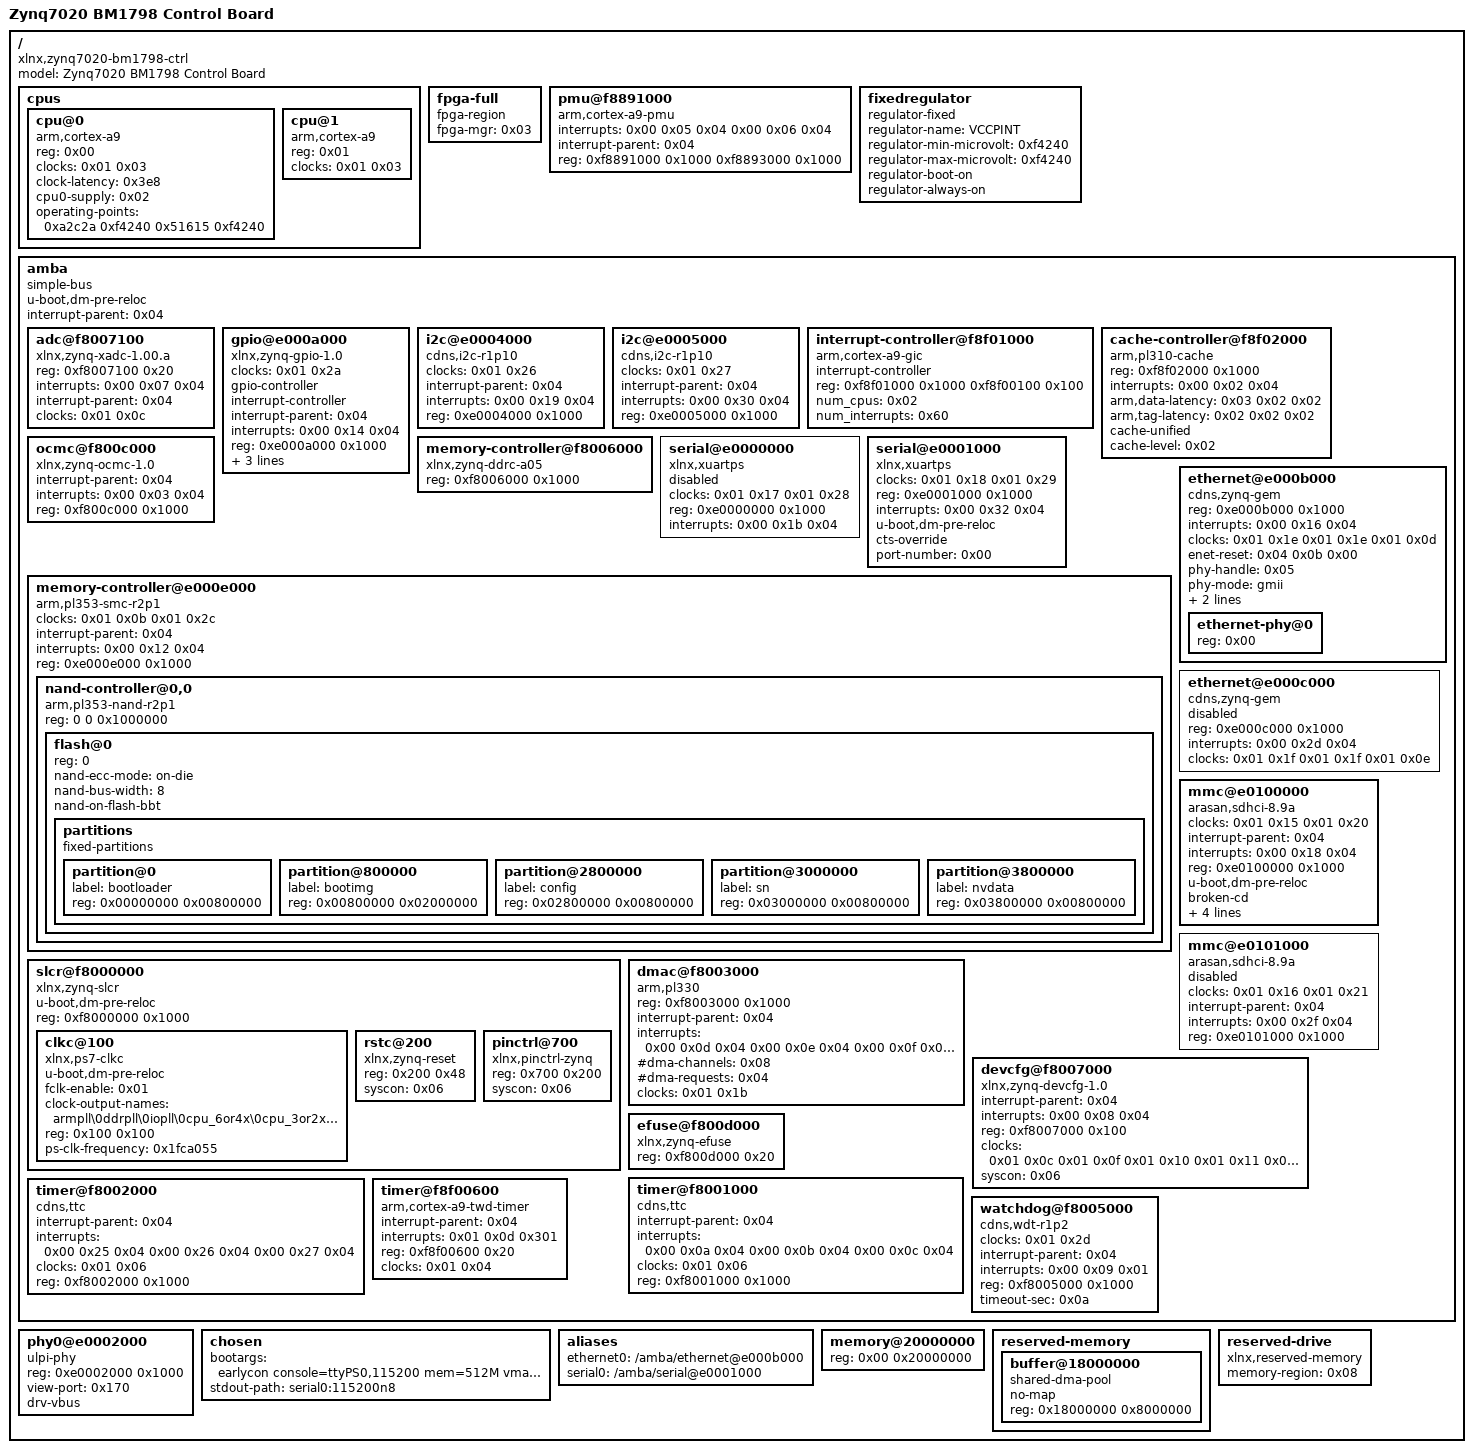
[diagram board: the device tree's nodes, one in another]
/dts-v1/;

/ {
	#address-cells = <0x01>;
	#size-cells = <0x01>;
	compatible = "xlnx,zynq7020-bm1798-ctrl\0xlnx,zynq-7000";
	model = "Zynq7020 BM1798 Control Board";

	cpus {
		#address-cells = <0x01>;
		#size-cells = <0x00>;

		cpu@0 {
			compatible = "arm,cortex-a9";
			device_type = "cpu";
			reg = <0x00>;
			clocks = <0x01 0x03>;
			clock-latency = <0x3e8>;
			cpu0-supply = <0x02>;
			operating-points = <0xa2c2a 0xf4240 0x51615 0xf4240>;
		};

		cpu@1 {
			compatible = "arm,cortex-a9";
			device_type = "cpu";
			reg = <0x01>;
			clocks = <0x01 0x03>;
		};
	};

	fpga-full {
		compatible = "fpga-region";
		fpga-mgr = <0x03>;
		#address-cells = <0x01>;
		#size-cells = <0x01>;
		ranges;
	};

	pmu@f8891000 {
		compatible = "arm,cortex-a9-pmu";
		interrupts = <0x00 0x05 0x04 0x00 0x06 0x04>;
		interrupt-parent = <0x04>;
		reg = <0xf8891000 0x1000 0xf8893000 0x1000>;
	};

	fixedregulator {
		compatible = "regulator-fixed";
		regulator-name = "VCCPINT";
		regulator-min-microvolt = <0xf4240>;
		regulator-max-microvolt = <0xf4240>;
		regulator-boot-on;
		regulator-always-on;
		phandle = <0x02>;
	};

	amba {
		u-boot,dm-pre-reloc;
		compatible = "simple-bus";
		#address-cells = <0x01>;
		#size-cells = <0x01>;
		interrupt-parent = <0x04>;
		ranges;

		adc@f8007100 {
			compatible = "xlnx,zynq-xadc-1.00.a";
			reg = <0xf8007100 0x20>;
			interrupts = <0x00 0x07 0x04>;
			interrupt-parent = <0x04>;
			clocks = <0x01 0x0c>;
		};

		gpio@e000a000 {
			compatible = "xlnx,zynq-gpio-1.0";
			#gpio-cells = <0x02>;
			clocks = <0x01 0x2a>;
			gpio-controller;
			interrupt-controller;
			#interrupt-cells = <0x02>;
			interrupt-parent = <0x04>;
			interrupts = <0x00 0x14 0x04>;
			reg = <0xe000a000 0x1000>;
			emio-gpio-width = <0x40>;
			gpio-mask-high = <0x00>;
			gpio-mask-low = <0x5600>;
		};

		i2c@e0004000 {
			compatible = "cdns,i2c-r1p10";
			status = "ok";
			clocks = <0x01 0x26>;
			interrupt-parent = <0x04>;
			interrupts = <0x00 0x19 0x04>;
			reg = <0xe0004000 0x1000>;
			#address-cells = <0x01>;
			#size-cells = <0x00>;
		};

		i2c@e0005000 {
			compatible = "cdns,i2c-r1p10";
			status = "ok";
			clocks = <0x01 0x27>;
			interrupt-parent = <0x04>;
			interrupts = <0x00 0x30 0x04>;
			reg = <0xe0005000 0x1000>;
			#address-cells = <0x01>;
			#size-cells = <0x00>;
		};

		interrupt-controller@f8f01000 {
			compatible = "arm,cortex-a9-gic";
			#interrupt-cells = <0x03>;
			interrupt-controller;
			reg = <0xf8f01000 0x1000 0xf8f00100 0x100>;
			num_cpus = <0x02>;
			num_interrupts = <0x60>;
			phandle = <0x04>;
		};

		cache-controller@f8f02000 {
			compatible = "arm,pl310-cache";
			reg = <0xf8f02000 0x1000>;
			interrupts = <0x00 0x02 0x04>;
			arm,data-latency = <0x03 0x02 0x02>;
			arm,tag-latency = <0x02 0x02 0x02>;
			cache-unified;
			cache-level = <0x02>;
		};

		memory-controller@f8006000 {
			compatible = "xlnx,zynq-ddrc-a05";
			reg = <0xf8006000 0x1000>;
		};

		ocmc@f800c000 {
			compatible = "xlnx,zynq-ocmc-1.0";
			interrupt-parent = <0x04>;
			interrupts = <0x00 0x03 0x04>;
			reg = <0xf800c000 0x1000>;
		};

		serial@e0000000 {
			compatible = "xlnx,xuartps\0cdns,uart-r1p8";
			status = "disabled";
			clocks = <0x01 0x17 0x01 0x28>;
			clock-names = "uart_clk\0pclk";
			reg = <0xe0000000 0x1000>;
			interrupts = <0x00 0x1b 0x04>;
		};

		serial@e0001000 {
			compatible = "xlnx,xuartps\0cdns,uart-r1p8";
			status = "okay";
			clocks = <0x01 0x18 0x01 0x29>;
			clock-names = "uart_clk\0pclk";
			reg = <0xe0001000 0x1000>;
			interrupts = <0x00 0x32 0x04>;
			u-boot,dm-pre-reloc;
			cts-override;
			device_type = "serial";
			port-number = <0x00>;
		};

		memory-controller@e000e000 {
			#address-cells = <2>;
			#size-cells = <1>;
			status = "okay";
			clock-names = "memclk", "apb_pclk";
			clocks = <0x01 0x0b 0x01 0x2c>;
			compatible = "arm,pl353-smc-r2p1", "arm,primecell";
			interrupt-parent = <0x04>;
			interrupts = <0x00 0x12 0x04>;
			ranges = <0x0 0x0 0xe1000000 0x1000000>;
			reg = <0xe000e000 0x1000>;

			nand-controller@0,0 {
				compatible = "arm,pl353-nand-r2p1";
				reg = <0 0 0x1000000>;
				#address-cells = <1>;
				#size-cells = <0>;
				status = "okay";
				flash@0 {
					reg = <0>;
					#address-cells = <1>;
					#size-cells = <1>;

					nand-ecc-mode = "on-die";
					/* nand-ecc-strength = <8>; */
					/* nand-ecc-step-size = <512>; */
					nand-bus-width = <8>;
					nand-on-flash-bbt;

					partitions {
						compatible = "fixed-partitions";
						#address-cells = <1>;
						#size-cells = <1>;

						partition@0 {
							label = "bootloader";
							reg = <0x00000000 0x00800000>;
						};
						partition@800000 {
							label = "bootimg";
							reg = <0x00800000 0x02000000>;
						};
						partition@2800000 {
							label = "config";
							reg = <0x02800000 0x00800000>;
						};
						partition@3000000 {
							label = "sn";
							reg = <0x03000000 0x00800000>;
						};
						partition@3800000 {
							label = "nvdata";
							reg = <0x03800000 0x00800000>;
						};
					};
				};
			};
		};

		ethernet@e000b000 {
			compatible = "cdns,zynq-gem\0cdns,gem";
			reg = <0xe000b000 0x1000>;
			status = "okay";
			interrupts = <0x00 0x16 0x04>;
			clocks = <0x01 0x1e 0x01 0x1e 0x01 0x0d>;
			clock-names = "pclk\0hclk\0tx_clk";
			enet-reset = <0x04 0x0b 0x00>;
			#address-cells = <0x01>;
			#size-cells = <0x00>;
			phy-handle = <0x05>;
			phy-mode = "gmii";
			xlnx,ptp-enet-clock = <0x69f6bcb>;
			local-mac-address = [00 0a 35 00 1e 53];

			ethernet-phy@0 {
				reg = <0x00>;
				device_type = "ethernet-phy";
				phandle = <0x05>;
			};
		};

		ethernet@e000c000 {
			compatible = "cdns,zynq-gem\0cdns,gem";
			reg = <0xe000c000 0x1000>;
			status = "disabled";
			interrupts = <0x00 0x2d 0x04>;
			clocks = <0x01 0x1f 0x01 0x1f 0x01 0x0e>;
			clock-names = "pclk\0hclk\0tx_clk";
			#address-cells = <0x01>;
			#size-cells = <0x00>;
		};

		mmc@e0100000 {
			compatible = "arasan,sdhci-8.9a";
			status = "okay";
			clock-names = "clk_xin\0clk_ahb";
			clocks = <0x01 0x15 0x01 0x20>;
			interrupt-parent = <0x04>;
			interrupts = <0x00 0x18 0x04>;
			reg = <0xe0100000 0x1000>;
			u-boot,dm-pre-reloc;
			broken-cd;
			wp-inverted;
			xlnx,has-cd = <0x01>;
			xlnx,has-power = <0x00>;
			xlnx,has-wp = <0x01>;
		};

		mmc@e0101000 {
			compatible = "arasan,sdhci-8.9a";
			status = "disabled";
			clock-names = "clk_xin\0clk_ahb";
			clocks = <0x01 0x16 0x01 0x21>;
			interrupt-parent = <0x04>;
			interrupts = <0x00 0x2f 0x04>;
			reg = <0xe0101000 0x1000>;
		};

		slcr@f8000000 {
			u-boot,dm-pre-reloc;
			#address-cells = <0x01>;
			#size-cells = <0x01>;
			compatible = "xlnx,zynq-slcr\0syscon\0simple-mfd";
			reg = <0xf8000000 0x1000>;
			ranges;
			phandle = <0x06>;

			clkc@100 {
				u-boot,dm-pre-reloc;
				#clock-cells = <0x01>;
				compatible = "xlnx,ps7-clkc";
				fclk-enable = <0x01>;
				clock-output-names = "armpll\0ddrpll\0iopll\0cpu_6or4x\0cpu_3or2x\0cpu_2x\0cpu_1x\0ddr2x\0ddr3x\0dci\0lqspi\0smc\0pcap\0gem0\0gem1\0fclk0\0fclk1\0fclk2\0fclk3\0can0\0can1\0sdio0\0sdio1\0uart0\0uart1\0spi0\0spi1\0dma\0usb0_aper\0usb1_aper\0gem0_aper\0gem1_aper\0sdio0_aper\0sdio1_aper\0spi0_aper\0spi1_aper\0can0_aper\0can1_aper\0i2c0_aper\0i2c1_aper\0uart0_aper\0uart1_aper\0gpio_aper\0lqspi_aper\0smc_aper\0swdt\0dbg_trc\0dbg_apb";
				reg = <0x100 0x100>;
				ps-clk-frequency = <0x1fca055>;
				phandle = <0x01>;
			};

			rstc@200 {
				compatible = "xlnx,zynq-reset";
				reg = <0x200 0x48>;
				#reset-cells = <0x01>;
				syscon = <0x06>;
			};

			pinctrl@700 {
				compatible = "xlnx,pinctrl-zynq";
				reg = <0x700 0x200>;
				syscon = <0x06>;
			};
		};

		dmac@f8003000 {
			compatible = "arm,pl330\0arm,primecell";
			reg = <0xf8003000 0x1000>;
			interrupt-parent = <0x04>;
			interrupt-names = "abort\0dma0\0dma1\0dma2\0dma3\0dma4\0dma5\0dma6\0dma7";
			interrupts = <0x00 0x0d 0x04 0x00 0x0e 0x04 0x00 0x0f 0x04 0x00 0x10 0x04 0x00 0x11 0x04 0x00 0x28 0x04 0x00 0x29 0x04 0x00 0x2a 0x04 0x00 0x2b 0x04>;
			#dma-cells = <0x01>;
			#dma-channels = <0x08>;
			#dma-requests = <0x04>;
			clocks = <0x01 0x1b>;
			clock-names = "apb_pclk";
		};

		devcfg@f8007000 {
			compatible = "xlnx,zynq-devcfg-1.0";
			interrupt-parent = <0x04>;
			interrupts = <0x00 0x08 0x04>;
			reg = <0xf8007000 0x100>;
			clocks = <0x01 0x0c 0x01 0x0f 0x01 0x10 0x01 0x11 0x01 0x12>;
			clock-names = "ref_clk\0fclk0\0fclk1\0fclk2\0fclk3";
			syscon = <0x06>;
			phandle = <0x03>;
		};

		efuse@f800d000 {
			compatible = "xlnx,zynq-efuse";
			reg = <0xf800d000 0x20>;
		};

		timer@f8001000 {
			interrupt-parent = <0x04>;
			interrupts = <0x00 0x0a 0x04 0x00 0x0b 0x04 0x00 0x0c 0x04>;
			compatible = "cdns,ttc";
			clocks = <0x01 0x06>;
			reg = <0xf8001000 0x1000>;
		};

		timer@f8002000 {
			interrupt-parent = <0x04>;
			interrupts = <0x00 0x25 0x04 0x00 0x26 0x04 0x00 0x27 0x04>;
			compatible = "cdns,ttc";
			clocks = <0x01 0x06>;
			reg = <0xf8002000 0x1000>;
		};

		timer@f8f00600 {
			interrupt-parent = <0x04>;
			interrupts = <0x01 0x0d 0x301>;
			compatible = "arm,cortex-a9-twd-timer";
			reg = <0xf8f00600 0x20>;
			clocks = <0x01 0x04>;
		};

		watchdog@f8005000 {
			clocks = <0x01 0x2d>;
			compatible = "cdns,wdt-r1p2";
			interrupt-parent = <0x04>;
			interrupts = <0x00 0x09 0x01>;
			reg = <0xf8005000 0x1000>;
			timeout-sec = <0x0a>;
		};
	};

	phy0@e0002000 {
		compatible = "ulpi-phy";
		#phy-cells = <0x00>;
		reg = <0xe0002000 0x1000>;
		view-port = <0x170>;
		drv-vbus;
		phandle = <0x07>;
	};

	chosen {
		bootargs = "earlycon console=ttyPS0,115200 mem=512M vmalloc=300M";
		stdout-path = "serial0:115200n8";
	};

	aliases {
		ethernet0 = "/amba/ethernet@e000b000";
		serial0 = "/amba/serial@e0001000";
	};

	memory@20000000 {
		device_type = "memory";
		reg = <0x00 0x20000000>;
	};

	reserved-memory {
		#address-cells = <0x01>;
		#size-cells = <0x01>;
		ranges;

		buffer@18000000 {
			compatible = "shared-dma-pool";
			no-map;
			reg = <0x18000000 0x8000000>;
			phandle = <0x08>;
		};
	};

	reserved-drive {
		compatible = "xlnx,reserved-memory";
		memory-region = <0x08>;
	};
};
